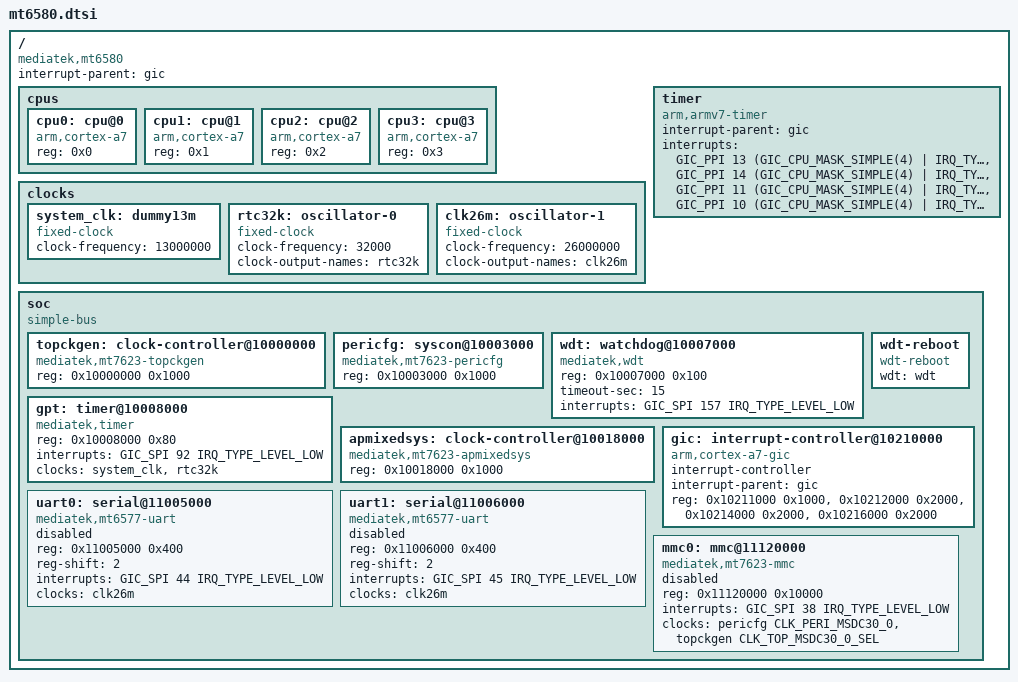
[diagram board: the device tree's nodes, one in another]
#include <dt-bindings/interrupt-controller/irq.h>
#include <dt-bindings/interrupt-controller/arm-gic.h>
#include <dt-bindings/phy/phy.h>
#include <dt-bindings/gpio/gpio.h>

#include <dt-bindings/clock/mt7623-clk.h>
#include <dt-bindings/power/mt7623-power.h>
#include <dt-bindings/reset/mt7623-reset.h>


/ {
  compatible = "mediatek,mt6580", "mediatek,MT6580";
  #address-cells = <1>;
  #size-cells = <1>;
  interrupt-parent = <&gic>;

  cpus {
    #address-cells = <1>;
    #size-cells = <0>;

    cpu0: cpu@0 {
      compatible = "arm,cortex-a7";
      device_type = "cpu";
      reg = <0x0>;
    };

    cpu1: cpu@1 {
      compatible = "arm,cortex-a7";
      device_type = "cpu";
      reg = <0x1>;
    };
    
    cpu2: cpu@2 {
      compatible = "arm,cortex-a7";
      device_type = "cpu";
      reg = <0x2>;
    };
    
    cpu3: cpu@3 {
      compatible = "arm,cortex-a7";
      device_type = "cpu";
      reg = <0x3>;
    };
  };

  clocks {
    #address-cells = <1>;
    #size-cells = <1>;
    ranges;

    system_clk: dummy13m {
      compatible = "fixed-clock";
      clock-frequency = <13000000>;
      #clock-cells = <0>;
    };

    rtc32k: oscillator-0 {
      compatible = "fixed-clock";
      clock-frequency = <32000>;
      #clock-cells = <0>;
      clock-output-names = "rtc32k";
    };

    clk26m: oscillator-1 {
      compatible = "fixed-clock";
      #clock-cells = <0>;
      clock-frequency = <26000000>;
      clock-output-names = "clk26m";
    };
  };
  
  timer {
    compatible = "arm,armv7-timer";
    interrupt-parent = <&gic>;
    interrupts =  <GIC_PPI 13 (GIC_CPU_MASK_SIMPLE(4) | IRQ_TYPE_LEVEL_HIGH)>,
                  <GIC_PPI 14 (GIC_CPU_MASK_SIMPLE(4) | IRQ_TYPE_LEVEL_HIGH)>,
                  <GIC_PPI 11 (GIC_CPU_MASK_SIMPLE(4) | IRQ_TYPE_LEVEL_HIGH)>,
                  <GIC_PPI 10 (GIC_CPU_MASK_SIMPLE(4) | IRQ_TYPE_LEVEL_HIGH)>;
  };

  soc {
    #address-cells = <1>;
    #size-cells = <1>;
    compatible = "simple-bus";
    ranges;
  
    topckgen: clock-controller@10000000 {
      // TODO: write a proper clock driver and nuke this
      compatible = "mediatek,mt7623-topckgen";
      reg = <0x10000000 0x1000>;
      #clock-cells = <1>;
    };

    pericfg: syscon@10003000 {
      // TODO: write a proper clock driver and nuke this
      compatible = "mediatek,mt7623-pericfg", "syscon";
      reg = <0x10003000 0x1000>;
      #clock-cells = <1>;
    };
  
    wdt: watchdog@10007000 {
      compatible = "mediatek,wdt";
      reg = <0x10007000 0x100>;
      timeout-sec = <15>;
      interrupts = <GIC_SPI 157 IRQ_TYPE_LEVEL_LOW>;
    };
    
    wdt-reboot {
      compatible = "wdt-reboot";
      wdt = <&wdt>;
    };

    gpt: timer@10008000 {
      compatible = "mediatek,timer";
      reg = <0x10008000 0x80>;
      interrupts = <GIC_SPI 92 IRQ_TYPE_LEVEL_LOW>;
      clocks = <&system_clk>, <&rtc32k>;
      clock-names = "system-clk", "rtc32k";
    };
    
    apmixedsys: clock-controller@10018000 {
      // TODO: write a proper clock driver and nuke this
      compatible = "mediatek,mt7623-apmixedsys";
      reg = <0x10018000 0x1000>;
      #clock-cells = <1>;
    };

    gic: interrupt-controller@10210000 {
      compatible = "arm,cortex-a7-gic";
      interrupt-controller;
      #interrupt-cells = <3>;
      interrupt-parent = <&gic>;
      reg = <0x10211000 0x1000>,
            <0x10212000 0x2000>,
            <0x10214000 0x2000>,
            <0x10216000 0x2000>;
    };

    uart0: serial@11005000 {
      compatible = "mediatek,mt6577-uart";
      reg = <0x11005000 0x400>;
      reg-shift = <2>;
      interrupts = <GIC_SPI 44 IRQ_TYPE_LEVEL_LOW>;
      // TODO: write a proper clock driver and nuke this
      clocks = <&clk26m>;
      status = "disabled";
    };

    uart1: serial@11006000 {
      compatible = "mediatek,mt6577-uart";
      reg = <0x11006000 0x400>;
      reg-shift = <2>;
      interrupts = <GIC_SPI 45 IRQ_TYPE_LEVEL_LOW>;
      // TODO: write a proper clock driver and nuke this
      clocks = <&clk26m>;
      status = "disabled";
    };

    mmc0: mmc@11120000 {
      compatible = "mediatek,mt7623-mmc";
      reg = <0x11120000 0x10000>;
      interrupts = <GIC_SPI 38 IRQ_TYPE_LEVEL_LOW>;
      clocks = <&pericfg CLK_PERI_MSDC30_0>,
               <&topckgen CLK_TOP_MSDC30_0_SEL>;
      clock-names = "source", "hclk";
      status = "disabled";
    };
  };
};
